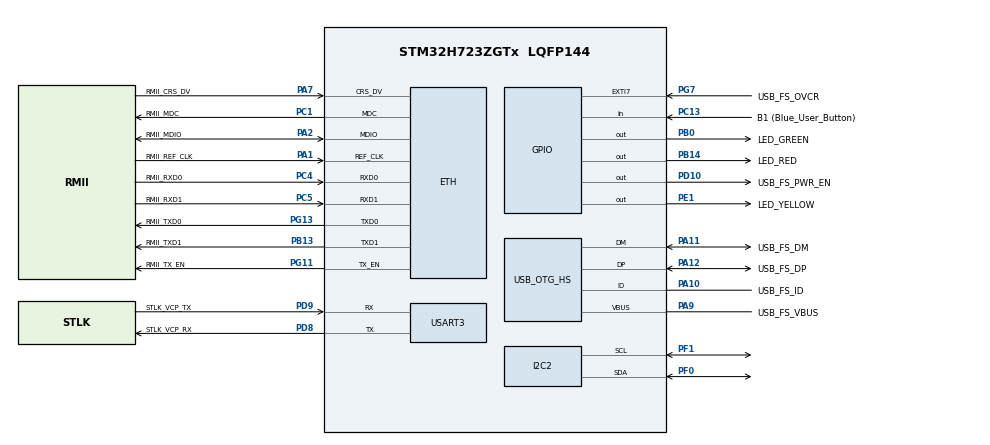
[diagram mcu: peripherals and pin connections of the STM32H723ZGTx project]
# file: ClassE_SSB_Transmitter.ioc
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ETH.MediaInterface=HAL_ETH_RMII_MODE
I2C2.Timing=0x60404E72
Mcu.Family=STM32H7
Mcu.Name=STM32H723ZGTx
Mcu.Package=LQFP144
NVIC.PriorityGroup=NVIC_PRIORITYGROUP_4
PA1.GPIO_Label=RMII_REF_CLK
PA1.Mode=RMII
PA1.Signal=ETH_REF_CLK
PA10.GPIO_Label=USB_FS_ID
PA10.Mode=OTG/Dual-Role-Device-FS
PA10.Signal=USB_OTG_HS_ID
PA11.GPIO_Label=USB_FS_DM
PA11.Mode=OTG/Dual-Role-Device-FS
PA11.Signal=USB_OTG_HS_DM
PA12.GPIO_Label=USB_FS_DP
PA12.Mode=OTG/Dual-Role-Device-FS
PA12.Signal=USB_OTG_HS_DP
PA13(JTMS/SWDIO).GPIO_Label=SWDIO
PA13(JTMS/SWDIO).Mode=Trace_Asynchronous_SW
PA13(JTMS/SWDIO).Signal=DEBUG_JTMS-SWDIO
PA14(JTCK/SWCLK).GPIO_Label=SWCLK
PA14(JTCK/SWCLK).Mode=Trace_Asynchronous_SW
PA14(JTCK/SWCLK).Signal=DEBUG_JTCK-SWCLK
PA2.GPIO_Label=RMII_MDIO
PA2.Mode=RMII
PA2.Signal=ETH_MDIO
PA7.GPIO_Label=RMII_CRS_DV
PA7.Mode=RMII
PA7.Signal=ETH_CRS_DV
PA9.GPIO_Label=USB_FS_VBUS
PA9.Mode=Activate_VBUS_FS
PA9.Signal=USB_OTG_HS_VBUS
PB0.GPIO_Label=LED_GREEN
PB0.Signal=GPIO_Output
PB13.GPIO_Label=RMII_TXD1
PB13.Mode=RMII
PB13.Signal=ETH_TXD1
PB14.GPIO_Label=LED_RED
PB14.Signal=GPIO_Output
PB3(JTDO/TRACESWO).GPIO_Label=SWO
PB3(JTDO/TRACESWO).Mode=Trace_Asynchronous_SW
PB3(JTDO/TRACESWO).Signal=DEBUG_JTDO-SWO
PC1.GPIO_Label=RMII_MDC
PC1.Mode=RMII
PC1.Signal=ETH_MDC
PC13.GPIO_Label=B1 (Blue_User_Button)
PC13.Signal=GPIO_Input
PC14-OSC32_IN.Mode=LSE-External-Oscillator
PC14-OSC32_IN.Signal=RCC_OSC32_IN
PC15-OSC32_OUT.Mode=LSE-External-Oscillator
PC15-OSC32_OUT.Signal=RCC_OSC32_OUT
PC4.GPIO_Label=RMII_RXD0
PC4.Mode=RMII
PC4.Signal=ETH_RXD0
PC5.GPIO_Label=RMII_RXD1
PC5.Mode=RMII
PC5.Signal=ETH_RXD1
PD10.GPIO_Label=USB_FS_PWR_EN
PD10.Signal=GPIO_Output
PD8.GPIO_Label=STLK_VCP_RX
PD8.Mode=Asynchronous
PD8.Signal=USART3_TX
PD9.GPIO_Label=STLK_VCP_TX
PD9.Mode=Asynchronous
PD9.Signal=USART3_RX
PE1.GPIO_Label=LED_YELLOW
PE1.Signal=GPIO_Output
PF0.Mode=I2C
PF0.Signal=I2C2_SDA
PF1.Mode=I2C
PF1.Signal=I2C2_SCL
PG11.GPIO_Label=RMII_TX_EN
PG11.Mode=RMII
PG11.Signal=ETH_TX_EN
PG13.GPIO_Label=RMII_TXD0
PG13.Mode=RMII
PG13.Signal=ETH_TXD0
PG7.GPIO_Label=USB_FS_OVCR
PG7.Signal=GPXTI7
PH0-OSC_IN.GPIO_Label=MCO
PH0-OSC_IN.Mode=HSE-External-Clock-Source
PH0-OSC_IN.Signal=RCC_OSC_IN
PH1-OSC_OUT.Signal=RCC_OSC_OUT
ProjectManager.HeapSize=0x200
ProjectManager.StackSize=0x400
ProjectManager.TargetToolchain=STM32CubeIDE
RCC.ADCFreq_Value=76000000
RCC.APB1Freq_Value=137500000
RCC.APB2Freq_Value=137500000
RCC.APB3Freq_Value=137500000
RCC.APB4Freq_Value=137500000
RCC.CortexFreq_Value=550000000
RCC.D1PPRE=RCC_APB3_DIV2
RCC.D2PPRE1=RCC_APB1_DIV2
RCC.D2PPRE2=RCC_APB2_DIV2
RCC.D3PPRE=RCC_APB4_DIV2
RCC.DIVM1=4
RCC.DIVM2=1
RCC.DIVN1=275
RCC.DIVN2=19
RCC.DIVP1=1
RCC.DIVQ1=4
RCC.HCLKFreq_Value=275000000
RCC.HPRE=RCC_HCLK_DIV2
RCC.HSE_VALUE=8000000
RCC.PLLFRACN=0
RCC.PLLSourceVirtual=RCC_PLLSOURCE_HSE
RCC.SYSCLKFreq_VALUE=550000000
RCC.SYSCLKSource=RCC_SYSCLKSOURCE_PLLCLK
RCC.USBCLockSelection=RCC_USBCLKSOURCE_HSI48
RCC.USBFreq_Value=48000000
USART3.VirtualMode-Asynchronous=VM_ASYNC
board=NUCLEO-H723ZG

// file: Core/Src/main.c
/* USER CODE BEGIN Header */
/**
  ******************************************************************************
  * @file           : main.c
  * @brief          : Main program body
  ******************************************************************************
  * @attention
  *
  * Copyright (c) 2023 STMicroelectronics.
  * All rights reserved.
  *
  * This software is licensed under terms that can be found in the LICENSE file
  * in the root directory of this software component.
  * If no LICENSE file comes with this software, it is provided AS-IS.
  *
  ******************************************************************************
  */
/* USER CODE END Header */
#include "main.h"
#include "eth.h"
#include "i2c.h"
#include "usart.h"
#include "usb_otg.h"
#include "gpio.h"

/* USER CODE BEGIN Includes */
#include "si5351.h"
#include "dwt_stm32_delay.h"
/* USER CODE END Includes */

/* USER CODE BEGIN PD */
#define DATA_SIZE 512
#define FULL_BUFFER_SIZE 1024
#define SAMPLE_RATE 7000
#define MAX_VALUE_FROM_ADC 0x0FFF

#define SI5351_CORRECTION 0
/* USER CODE END PD */

void SystemClock_Config(void);

int main(void)
{

  /* MCU Configuration--------------------------------------------------------*/

  /* Reset of all peripherals, Initializes the Flash interface and the Systick. */
  HAL_Init();

  /* Configure the system clock */
  SystemClock_Config();

  /* Initialize all configured peripherals */
  MX_GPIO_Init();
  MX_ETH_Init();
  MX_USART3_UART_Init();
  MX_USB_OTG_HS_USB_Init();
  MX_I2C2_Init();
  /* USER CODE BEGIN 2 */
  si5351_Init(SI5351_CORRECTION);

  si5351_SetupCLK0(14000000, SI5351_DRIVE_STRENGTH_8MA);
  si5351_EnableOutputs(1 << 0);
  /* USER CODE END 2 */

  /* Infinite loop */
  while (1)
  {
	for (int i = 0; i < DATA_SIZE; i++) {
		if (i == 142) {
			si5351_SetupCLK0(14001000, SI5351_DRIVE_STRENGTH_8MA);
			si5351_EnableOutputs(1 << 0);
			//HAL_Delay(1);
			DWT_Delay_us(142);
		} else if (i == 214) {
			si5351_SetupCLK0(14001500, SI5351_DRIVE_STRENGTH_8MA);
			si5351_EnableOutputs(1 << 0);
			DWT_Delay_us(142);
		} else {
            si5351_EnableOutputs(0);
		}
	}
  }
}

void SystemClock_Config(void)
{
  RCC_OscInitTypeDef RCC_OscInitStruct = {0};
  RCC_ClkInitTypeDef RCC_ClkInitStruct = {0};

  /** Supply configuration update enable
  */
  HAL_PWREx_ConfigSupply(PWR_LDO_SUPPLY);

  /** Configure the main internal regulator output voltage
  */
  __HAL_PWR_VOLTAGESCALING_CONFIG(PWR_REGULATOR_VOLTAGE_SCALE0);

  while(!__HAL_PWR_GET_FLAG(PWR_FLAG_VOSRDY)) {}

  /** Initializes the RCC Oscillators according to the specified parameters
  * in the RCC_OscInitTypeDef structure.
  */
  RCC_OscInitStruct.OscillatorType = RCC_OSCILLATORTYPE_HSI48|RCC_OSCILLATORTYPE_HSE;
  RCC_OscInitStruct.HSEState = RCC_HSE_BYPASS;
  RCC_OscInitStruct.HSI48State = RCC_HSI48_ON;
  RCC_OscInitStruct.PLL.PLLState = RCC_PLL_ON;
  RCC_OscInitStruct.PLL.PLLSource = RCC_PLLSOURCE_HSE;
  RCC_OscInitStruct.PLL.PLLM = 4;
  RCC_OscInitStruct.PLL.PLLN = 275;
  RCC_OscInitStruct.PLL.PLLP = 1;
  RCC_OscInitStruct.PLL.PLLQ = 4;
  RCC_OscInitStruct.PLL.PLLR = 2;
  RCC_OscInitStruct.PLL.PLLRGE = RCC_PLL1VCIRANGE_1;
  RCC_OscInitStruct.PLL.PLLVCOSEL = RCC_PLL1VCOWIDE;
  RCC_OscInitStruct.PLL.PLLFRACN = 0;
  if (HAL_RCC_OscConfig(&RCC_OscInitStruct) != HAL_OK)
  {
    Error_Handler();
  }

  /** Initializes the CPU, AHB and APB buses clocks
  */
  RCC_ClkInitStruct.ClockType = RCC_CLOCKTYPE_HCLK|RCC_CLOCKTYPE_SYSCLK
                              |RCC_CLOCKTYPE_PCLK1|RCC_CLOCKTYPE_PCLK2
                              |RCC_CLOCKTYPE_D3PCLK1|RCC_CLOCKTYPE_D1PCLK1;
  RCC_ClkInitStruct.SYSCLKSource = RCC_SYSCLKSOURCE_PLLCLK;
  RCC_ClkInitStruct.SYSCLKDivider = RCC_SYSCLK_DIV1;
  RCC_ClkInitStruct.AHBCLKDivider = RCC_HCLK_DIV2;
  RCC_ClkInitStruct.APB3CLKDivider = RCC_APB3_DIV2;
  RCC_ClkInitStruct.APB1CLKDivider = RCC_APB1_DIV2;
  RCC_ClkInitStruct.APB2CLKDivider = RCC_APB2_DIV2;
  RCC_ClkInitStruct.APB4CLKDivider = RCC_APB4_DIV2;

  if (HAL_RCC_ClockConfig(&RCC_ClkInitStruct, FLASH_LATENCY_3) != HAL_OK)
  {
    Error_Handler();
  }
}

void Error_Handler(void)
{
  __disable_irq();
  while (1)
  {
  }
}
